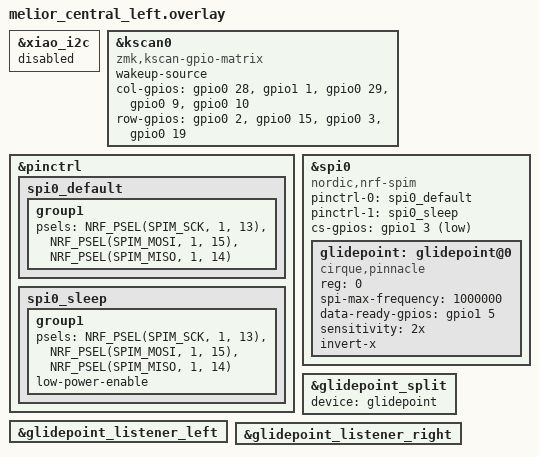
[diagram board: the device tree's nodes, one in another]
 #include "melior.dtsi"
#include <input/processors.dtsi>
#include <dt-bindings/zmk/input_transform.h>

&xiao_i2c {
    status = "disabled";
};

 &kscan0 {
    compatible = "zmk,kscan-gpio-matrix";
    wakeup-source;

    col-gpios
        = <&gpio0 28 GPIO_ACTIVE_HIGH> //Col 0
        , <&gpio1 1 GPIO_ACTIVE_HIGH> //Col 1
        , <&gpio0 29 GPIO_ACTIVE_HIGH> //Col 2
        , <&gpio0 9 GPIO_ACTIVE_HIGH> //Col 3
        , <&gpio0 10 GPIO_ACTIVE_HIGH> //Col 4
        ;

    row-gpios
        = <&gpio0 2 (GPIO_ACTIVE_HIGH | GPIO_PULL_DOWN)> //Row 0
        , <&gpio0 15 (GPIO_ACTIVE_HIGH | GPIO_PULL_DOWN)> //Row 1
        , <&gpio0 3 (GPIO_ACTIVE_HIGH | GPIO_PULL_DOWN)> //Row 2
        , <&gpio0 19 (GPIO_ACTIVE_HIGH | GPIO_PULL_DOWN)> //Row 3
        ;
 };

&pinctrl {
    spi0_default: spi0_default {
        group1 {
            psels = <NRF_PSEL(SPIM_SCK, 1, 13)>,
                <NRF_PSEL(SPIM_MOSI, 1, 15)>,
                <NRF_PSEL(SPIM_MISO, 1, 14)>;
        };
    };

     spi0_sleep: spi0_sleep {
        group1 {
            psels = <NRF_PSEL(SPIM_SCK, 1, 13)>,
                    <NRF_PSEL(SPIM_MOSI, 1, 15)>,
                    <NRF_PSEL(SPIM_MISO, 1, 14)>;
            low-power-enable;
        };
    };

};

&spi0 {
   compatible = "nordic,nrf-spim";
   status = "okay";
   pinctrl-0 = <&spi0_default>;
   pinctrl-1 = <&spi0_sleep>;
   pinctrl-names = "default", "sleep";
   cs-gpios = <&gpio1 3 GPIO_ACTIVE_LOW>;
   glidepoint:  glidepoint@0 {
        compatible = "cirque,pinnacle";
        reg = <0>;
        spi-max-frequency = <1000000>;
        status = "okay";
        data-ready-gpios = <&gpio1 5 (GPIO_ACTIVE_HIGH)>;
        sensitivity = "2x";
        invert-x;
	    //sleep;
    };
};

&glidepoint_split {
    device = <&glidepoint>;

    // Optional
    // input-processors = <&zip_xy_transform (INPUT_TRANSFORM_XY_SWAP | INPUT_TRANSFORM_X_INVERT | INPUT_TRANSFORM_Y_INVERT)>;
};

&glidepoint_listener_left {
    status = "okay";
};


&glidepoint_listener_right {
    status = "okay";
};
